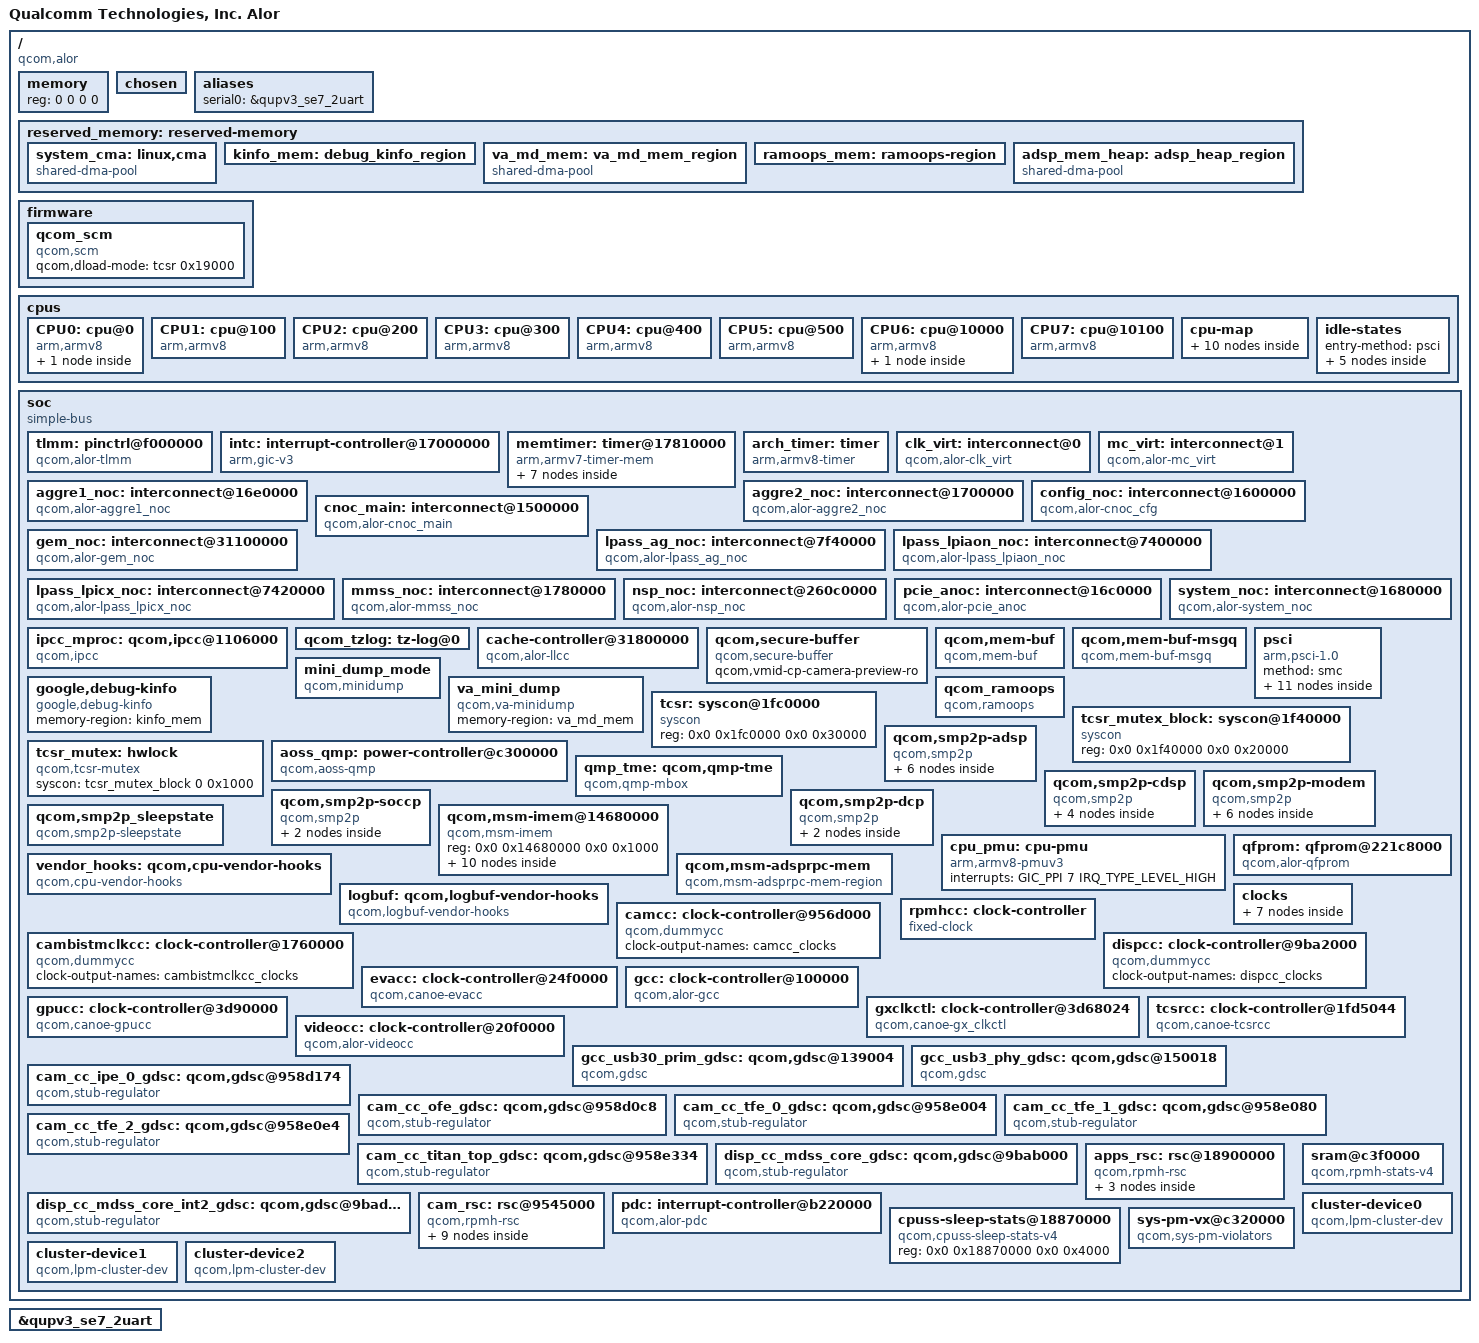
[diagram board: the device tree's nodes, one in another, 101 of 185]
// SPDX-License-Identifier: BSD-3-Clause
/*
 * Copyright (c) 2024-2025 Qualcomm Innovation Center, Inc. All rights reserved.
 */

#include <dt-bindings/clock/qcom,alor-cambistmclkcc.h>
#include <dt-bindings/clock/qcom,alor-camcc.h>
#include <dt-bindings/clock/qcom,alor-dispcc.h>
#include <dt-bindings/clock/qcom,evacc-canoe.h>
#include <dt-bindings/clock/qcom,alor-gcc.h>
#include <dt-bindings/clock/qcom,gpucc-canoe.h>
#include <dt-bindings/clock/qcom,gxclkctl-canoe.h>
#include <dt-bindings/clock/qcom,tcsrcc-canoe.h>
#include <dt-bindings/clock/qcom,videocc-canoe.h>
#include <dt-bindings/clock/qcom,rpmh.h>
#include <dt-bindings/interrupt-controller/arm-gic.h>
#include <dt-bindings/soc/qcom,rpmh-rsc.h>
#include <dt-bindings/interconnect/qcom,icc.h>
#include <dt-bindings/interconnect/qcom,alor.h>
#include <dt-bindings/soc/qcom,ipcc.h>
#include <dt-bindings/mailbox/qcom-ipcc-canoe.h>

/ {
	model = "Qualcomm Technologies, Inc. Alor";
	compatible = "qcom,alor";
	qcom,msm-id = <685 0x10000>;
	interrupt-parent = <&intc>;

	#address-cells = <2>;
	#size-cells = <2>;
	memory { device_type = "memory"; reg = <0 0 0 0>; };


	chosen: chosen {
		bootargs = "loglevel=6 kpti=0 loop.max_part=7 log_buf_len=512K kernel.panic_on_rcu_stall=1 msm_rtb.filter=0x237 rcupdate.rcu_expedited=1 rcu_nocbs=0-7 ftrace_dump_on_oops cpufreq.default_governor=performance printk.console_no_auto_verbose=1 irqaffinity=0-1";
		stdout-path = "/soc/qcom,qupv3_1_geni_se@ac0000/qcom,qup_uart@a9c000:115200n8";
	};

	aliases {
		serial0 = &qupv3_se7_2uart;
	};

	reserved_memory: reserved-memory { };

	firmware: firmware {
		qcom_scm: qcom_scm {
			compatible = "qcom,scm";
			qcom,dload-mode = <&tcsr 0x19000>;
		};
	};

	cpus {
		#address-cells = <2>;
		#size-cells = <0>;

		CPU0: cpu@0 {
			device_type = "cpu";
			compatible = "arm,armv8";
			reg = <0x0 0x0>;
			enable-method = "psci";
			cpu-idle-states = <&MEDIUM_OFF_C4>;
			power-domains = <&CPU_PD0>;
			power-domain-names = "psci";
			capacity-dmips-mhz = <1024>;
			dynamic-power-coefficient = <100>;
			next-level-cache = <&L2_0>;
			L2_0: l2-cache {
				compatible = "cache";
				cache-level = <2>;
			};
		};

		CPU1: cpu@100 {
			device_type = "cpu";
			compatible = "arm,armv8";
			reg = <0x0 0x100>;
			enable-method = "psci";
			cpu-idle-states = <&MEDIUM_OFF_C4>;
			power-domains = <&CPU_PD1>;
			power-domain-names = "psci";
			capacity-dmips-mhz = <1024>;
			dynamic-power-coefficient = <100>;
			next-level-cache = <&L2_0>;
		};

		CPU2: cpu@200 {
			device_type = "cpu";
			compatible = "arm,armv8";
			reg = <0x0 0x200>;
			enable-method = "psci";
			cpu-idle-states = <&MEDIUM_OFF_C4>;
			power-domains = <&CPU_PD2>;
			power-domain-names = "psci";
			capacity-dmips-mhz = <1024>;
			dynamic-power-coefficient = <100>;
			next-level-cache = <&L2_0>;
		};

		CPU3: cpu@300 {
			device_type = "cpu";
			compatible = "arm,armv8";
			reg = <0x0 0x300>;
			enable-method = "psci";
			cpu-idle-states = <&MEDIUM_OFF_C4>;
			power-domains = <&CPU_PD3>;
			power-domain-names = "psci";
			capacity-dmips-mhz = <1024>;
			dynamic-power-coefficient = <100>;
			next-level-cache = <&L2_0>;
		};

		CPU4: cpu@400 {
			device_type = "cpu";
			compatible = "arm,armv8";
			reg = <0x0 0x400>;
			enable-method = "psci";
			cpu-idle-states = <&MEDIUM_OFF_C4>;
			power-domains = <&CPU_PD4>;
			power-domain-names = "psci";
			capacity-dmips-mhz = <1024>;
			dynamic-power-coefficient = <100>;
			next-level-cache = <&L2_0>;
		};

		CPU5: cpu@500 {
			device_type = "cpu";
			compatible = "arm,armv8";
			reg = <0x0 0x500>;
			enable-method = "psci";
			cpu-idle-states = <&MEDIUM_OFF_C4>;
			power-domains = <&CPU_PD5>;
			power-domain-names = "psci";
			capacity-dmips-mhz = <1024>;
			dynamic-power-coefficient = <100>;
			next-level-cache = <&L2_0>;
		};

		CPU6: cpu@10000 {
			device_type = "cpu";
			compatible = "arm,armv8";
			reg = <0x0 0x10000>;
			enable-method = "psci";
			cpu-idle-states = <&LARGE_OFF_C4>;
			power-domains = <&CPU_PD6>;
			power-domain-names = "psci";
			capacity-dmips-mhz = <1208>;
			dynamic-power-coefficient = <271>;
			next-level-cache = <&L2_6>;
			L2_6: l2-cache {
				compatible = "cache";
				cache-level = <2>;
			};
		};

		CPU7: cpu@10100 {
			device_type = "cpu";
			compatible = "arm,armv8";
			reg = <0x0 0x10100>;
			enable-method = "psci";
			cpu-idle-states = <&LARGE_OFF_C4>;
			power-domains = <&CPU_PD7>;
			power-domain-names = "psci";
			capacity-dmips-mhz = <1208>;
			dynamic-power-coefficient = <271>;
			next-level-cache = <&L2_6>;
		};

		cpu-map {
			cluster0 {
				core0 {
					cpu = <&CPU0>;
				};

				core1 {
					cpu = <&CPU1>;
				};

				core2 {
					cpu = <&CPU2>;
				};

				core3 {
					cpu = <&CPU3>;
				};

				core4 {
					cpu = <&CPU4>;
				};

				core5 {
					cpu = <&CPU5>;
				};
			};

			cluster1 {
				core0 {
					cpu = <&CPU6>;
				};

				core1 {
					cpu = <&CPU7>;
				};
			};
		};

		idle-states {
			entry-method = "psci";

			MEDIUM_OFF_C4: medium-cluster0-c4 { /* C4 */
				compatible = "arm,idle-state";
				idle-state-name = "ret";
				entry-latency-us = <93>;
				exit-latency-us = <129>;
				min-residency-us = <560>;
				arm,psci-suspend-param = <0x00000004>;
			};

			LARGE_OFF_C4: large-cluster1-c4 { /* C4 */
				compatible = "arm,idle-state";
				idle-state-name = "ret";
				entry-latency-us = <172>;
				exit-latency-us = <130>;
				min-residency-us = <686>;
				arm,psci-suspend-param = <0x00000004>;
			};

			MEDIUM_CLUSTER_PWR_DN: medium-cluster-cl5 { /* CL5 */
				compatible = "domain-idle-state";
				entry-latency-us = <2150>;
				exit-latency-us = <1983>;
				min-residency-us = <9144>;
				arm,psci-suspend-param = <0x01000054>;
			};

			LARGE_CLUSTER_PWR_DN: large-cluster-cl5 { /* CL5 */
				compatible = "domain-idle-state";
				entry-latency-us = <2150>;
				exit-latency-us = <1983>;
				min-residency-us = <9144>;
				arm,psci-suspend-param = <0x01000054>;
			};

			APSS_OFF: cluster-ss3 { /* SS3 */
				compatible = "domain-idle-state";
				entry-latency-us = <2800>;
				exit-latency-us = <4400>;
				min-residency-us = <10150>;
				arm,psci-suspend-param = <0x0200B354>;
			};
		};
	};

	soc: soc { };
};

#include "alor-reserved-memory.dtsi"
#include "msm-arm-smmu-alor.dtsi"
#include "alor-dma-heaps.dtsi"

&reserved_memory {
	#address-cells = <2>;
	#size-cells = <2>;
	ranges;

	/* global autoconfigured region for contiguous allocations */
	system_cma: linux,cma {
		compatible = "shared-dma-pool";
		alloc-ranges = <0x0 0x00000000 0x0 0xffffffff>;
		reusable;
		alignment = <0x0 0x400000>;
		size = <0x0 0x2400000>;
		linux,cma-default;
	};

	kinfo_mem: debug_kinfo_region {
		alloc-ranges = <0x0 0x00000000 0xffffffff 0xffffffff>;
		size = <0x0 0x1000>;
		no-map;
	};

	va_md_mem: va_md_mem_region {
		compatible = "shared-dma-pool";
		alloc-ranges = <0x0 0x00000000 0x0 0xffffffff>;
		reusable;
		size = <0 0x1000000>;
	};

	ramoops_mem: ramoops-region {
		alloc-ranges = <0x1 0x00000000 0xfffffffe 0xffffffff>;
		size = <0x0 0x200000>;
		no-map;
	};

	adsp_mem_heap: adsp_heap_region {
		compatible = "shared-dma-pool";
		alloc-ranges = <0x0 0x00000000 0x0 0xffffffff>;
		reusable;
		alignment = <0x0 0x400000>;
		size = <0x0 0xC00000>;
	};
};

&soc {
	#address-cells = <2>;
	#size-cells = <2>;
	ranges = <0 0 0 0 0x10 0>;
	compatible = "simple-bus";

	tlmm: pinctrl@f000000 {
		compatible = "qcom,alor-tlmm";
		reg = <0x0 0xf000000 0x0 0x1000000>;
		interrupts = <GIC_SPI 208 IRQ_TYPE_LEVEL_HIGH>;
		gpio-controller;
		#gpio-cells = <2>;
		interrupt-controller;
		#interrupt-cells = <2>;
		wakeup-parent = <&pdc>;
	};

	intc: interrupt-controller@17000000 {
		compatible = "arm,gic-v3";
		#interrupt-cells = <3>;
		interrupt-controller;
		#redistributor-regions = <1>;
		redistributor-stride = <0x0 0x40000>;
		reg = <0x0 0x17000000 0x0 0x10000>,	/* GICD */
		      <0x0 0x17080000 0x0 0x200000>;	/* GICR * 8 */
		interrupts = <GIC_PPI 9 IRQ_TYPE_LEVEL_HIGH>;
	};

	memtimer: timer@17810000 {
		#address-cells = <1>;
		#size-cells = <1>;
		ranges;
		compatible = "arm,armv7-timer-mem";
		reg = <0x0 0x17810000 0x0 0x1000>;
		clock-frequency = <19200000>;

		frame@17811000 {
			frame-number = <0>;
			interrupts = <GIC_SPI 8 IRQ_TYPE_LEVEL_HIGH>,
				     <GIC_SPI 6 IRQ_TYPE_LEVEL_HIGH>;
			reg = <0x17811000 0x1000>,
			      <0x17812000 0x1000>;
		};

		frame@17813000 {
			frame-number = <1>;
			interrupts = <GIC_SPI 9 IRQ_TYPE_LEVEL_HIGH>;
			reg = <0x17813000 0x1000>;
			status = "disabled";
		};

		frame@17815000 {
			frame-number = <2>;
			interrupts = <GIC_SPI 10 IRQ_TYPE_LEVEL_HIGH>;
			reg = <0x17815000 0x1000>;
			status = "disabled";
		};

		frame@17817000 {
			frame-number = <3>;
			interrupts = <GIC_SPI 11 IRQ_TYPE_LEVEL_HIGH>;
			reg = <0x17817000 0x1000>;
			status = "disabled";
		};

		frame@17819000 {
			frame-number = <4>;
			interrupts = <GIC_SPI 12 IRQ_TYPE_LEVEL_HIGH>;
			reg = <0x17819000 0x1000>;
			status = "disabled";
		};

		frame@1781b000 {
			frame-number = <5>;
			interrupts = <GIC_SPI 13 IRQ_TYPE_LEVEL_HIGH>;
			reg = <0x1781b000 0x1000>;
			status = "disabled";
		};

		frame@1781d000 {
			frame-number = <6>;
			interrupts = <GIC_SPI 14 IRQ_TYPE_LEVEL_HIGH>;
			reg = <0x1781d000 0x1000>;
			status = "disabled";
		};
	};

	arch_timer: timer {
		compatible = "arm,armv8-timer";
		interrupts = <GIC_PPI 13 (GIC_CPU_MASK_SIMPLE(8) | IRQ_TYPE_LEVEL_LOW)>,
			     <GIC_PPI 14 (GIC_CPU_MASK_SIMPLE(8) | IRQ_TYPE_LEVEL_LOW)>,
			     <GIC_PPI 11 (GIC_CPU_MASK_SIMPLE(8) | IRQ_TYPE_LEVEL_LOW)>,
			     <GIC_PPI 10 (GIC_CPU_MASK_SIMPLE(8) | IRQ_TYPE_LEVEL_LOW)>;
		clock-frequency = <19200000>;
	};

	clk_virt: interconnect@0 {
		compatible = "qcom,alor-clk_virt";
		#interconnect-cells = <1>;
		qcom,bcm-voter-names = "hlos";
		qcom,bcm-voters = <&apps_bcm_voter>;
		qcom,skip-qos;
	};

	mc_virt: interconnect@1 {
		compatible = "qcom,alor-mc_virt";
		#interconnect-cells = <1>;
		qcom,bcm-voter-names = "hlos";
		qcom,bcm-voters = <&apps_bcm_voter>;
		qcom,skip-qos;
	};

	aggre1_noc: interconnect@16e0000 {
		compatible = "qcom,alor-aggre1_noc";
		reg = <0x0 0x16e0000 0x0 0x16400>;
		#interconnect-cells = <1>;
		qcom,bcm-voter-names = "hlos";
		qcom,bcm-voters = <&apps_bcm_voter>;
		qcom,skip-qos;
	};

	aggre2_noc: interconnect@1700000 {
		compatible = "qcom,alor-aggre2_noc";
		reg = <0x0 0x1700000 0x0 0x22400>;
		#interconnect-cells = <1>;
		qcom,bcm-voter-names = "hlos";
		qcom,bcm-voters = <&apps_bcm_voter>;
		qcom,skip-qos;
	};

	config_noc: interconnect@1600000 {
		compatible = "qcom,alor-cnoc_cfg";
		reg = <0x0 0x1600000 0x0 0x9200>;
		#interconnect-cells = <1>;
		qcom,bcm-voter-names = "hlos";
		qcom,bcm-voters = <&apps_bcm_voter>;
		qcom,skip-qos;
	};

	cnoc_main: interconnect@1500000 {
		compatible = "qcom,alor-cnoc_main";
		reg = <0x0 0x1500000 0x0 0x1a080>;
		#interconnect-cells = <1>;
		qcom,bcm-voter-names = "hlos";
		qcom,bcm-voters = <&apps_bcm_voter>;
		qcom,skip-qos;
	};

	gem_noc: interconnect@31100000 {
		compatible = "qcom,alor-gem_noc";
		reg = <0x0 0x31100000 0x0 0x153080>;
		#interconnect-cells = <1>;
		qcom,bcm-voter-names = "hlos";
		qcom,bcm-voters = <&apps_bcm_voter>;
		qcom,skip-qos;
	};

	lpass_ag_noc: interconnect@7f40000 {
		compatible = "qcom,alor-lpass_ag_noc";
		reg = <0x0 0x7f40000 0x0 0xe080>;
		#interconnect-cells = <1>;
		qcom,bcm-voter-names = "hlos";
		qcom,bcm-voters = <&apps_bcm_voter>;
		qcom,skip-qos;
	};

	lpass_lpiaon_noc: interconnect@7400000 {
		compatible = "qcom,alor-lpass_lpiaon_noc";
		reg = <0x0 0x7400000 0x0 0x19080>;
		#interconnect-cells = <1>;
		qcom,bcm-voter-names = "hlos";
		qcom,bcm-voters = <&apps_bcm_voter>;
		qcom,skip-qos;
	};

	lpass_lpicx_noc: interconnect@7420000 {
		compatible = "qcom,alor-lpass_lpicx_noc";
		reg = <0x0 0x7420000 0x0 0x44080>;
		#interconnect-cells = <1>;
		qcom,bcm-voter-names = "hlos";
		qcom,bcm-voters = <&apps_bcm_voter>;
		qcom,skip-qos;
	};

	mmss_noc: interconnect@1780000 {
		compatible = "qcom,alor-mmss_noc";
		reg = <0x0 0x1780000 0x0 0x7d400>;
		#interconnect-cells = <1>;
		qcom,bcm-voter-names = "hlos";
		qcom,bcm-voters = <&apps_bcm_voter>;
		qcom,skip-qos;
	};

	nsp_noc: interconnect@260c0000 {
		compatible = "qcom,alor-nsp_noc";
		reg = <0x0 0x260c0000 0x0 0x1c080>;
		#interconnect-cells = <1>;
		qcom,bcm-voter-names = "hlos";
		qcom,bcm-voters = <&apps_bcm_voter>;
		qcom,skip-qos;
	};

	pcie_anoc: interconnect@16c0000 {
		compatible = "qcom,alor-pcie_anoc";
		reg = <0x0 0x16c0000 0x0 0x11400>;
		#interconnect-cells = <1>;
		qcom,bcm-voter-names = "hlos";
		qcom,bcm-voters = <&apps_bcm_voter>;
		qcom,skip-qos;
	};

	system_noc: interconnect@1680000 {
		compatible = "qcom,alor-system_noc";
		reg = <0x0 0x1680000 0x0 0x1f080>;
		#interconnect-cells = <1>;
		qcom,bcm-voter-names = "hlos";
		qcom,bcm-voters = <&apps_bcm_voter>;
		qcom,skip-qos;
	};

	ipcc_mproc: qcom,ipcc@1106000 {
		compatible = "qcom,ipcc";
		reg = <0x0 0x1106000 0x0 0x1000>;
		interrupts = <GIC_SPI 246 IRQ_TYPE_LEVEL_HIGH>;
		interrupt-controller;
		#interrupt-cells = <3>;
		#mbox-cells = <2>;
	};

	qcom_tzlog: tz-log@0 {
	};

	cache-controller@31800000 {
		compatible = "qcom,alor-llcc";
		reg = <0x0 0x31800000 0x0 0x200000>, <0x0 0x32800000 0x0 0x200000>,
			<0x0 0x31C00000 0x0 0x200000>, <0x0 0x32C00000 0x0 0x200000>,
			<0x0 0x34800000 0x0 0x200000>, <0x0 0x34C00000 0x0 0x200000>;
		reg-names = "llcc0_base", "llcc1_base", "llcc2_base",
			"llcc3_base", "llcc_broadcast_or_base",
			"llcc_broadcast_and_base";
		interrupts = <GIC_SPI 266 IRQ_TYPE_LEVEL_HIGH>;
		cap-based-alloc-and-pwr-collapse;
	};

	qcom,secure-buffer {
		compatible = "qcom,secure-buffer";
		qcom,vmid-cp-camera-preview-ro;
	};

	qcom,mem-buf {
		compatible = "qcom,mem-buf";
		qcom,mem-buf-capabilities = "supplier";
		qcom,vmid = <3>;
	};

	qcom,mem-buf-msgq {
		compatible = "qcom,mem-buf-msgq";
	};

	psci {
		compatible = "arm,psci-1.0";
		method = "smc";

		CPU_PD0: cpu-pd0 {
			#power-domain-cells = <0>;
			power-domains = <&CLUSTER_PD0>;
		};

		CPU_PD1: cpu-pd1 {
			#power-domain-cells = <0>;
			power-domains = <&CLUSTER_PD0>;
		};

		CPU_PD2: cpu-pd2 {
			#power-domain-cells = <0>;
			power-domains = <&CLUSTER_PD0>;
		};

		CPU_PD3: cpu-pd3 {
			#power-domain-cells = <0>;
			power-domains = <&CLUSTER_PD0>;
		};

		CPU_PD4: cpu-pd4 {
			#power-domain-cells = <0>;
			power-domains = <&CLUSTER_PD0>;
		};

		CPU_PD5: cpu-pd5 {
			#power-domain-cells = <0>;
			power-domains = <&CLUSTER_PD0>;
		};

		CPU_PD6: cpu-pd6 {
			#power-domain-cells = <0>;
			power-domains = <&CLUSTER_PD1>;
		};

		CPU_PD7: cpu-pd7 {
			#power-domain-cells = <0>;
			power-domains = <&CLUSTER_PD1>;
		};

		CLUSTER_PD0: cluster-pd0 {
			#power-domain-cells = <0>;
			power-domains = <&CLUSTER_PD2>;
			domain-idle-states = <&MEDIUM_CLUSTER_PWR_DN>;
		};

		CLUSTER_PD1: cluster-pd1 {
			#power-domain-cells = <0>;
			power-domains = <&CLUSTER_PD2>;
			domain-idle-states = <&LARGE_CLUSTER_PWR_DN>;
		};

		CLUSTER_PD2: cluster-pd2 {
			#power-domain-cells = <0>;
			domain-idle-states = <&APSS_OFF>;
		};
	};

	google,debug-kinfo {
		compatible = "google,debug-kinfo";
		memory-region = <&kinfo_mem>;
	};

	mini_dump_mode {
		compatible = "qcom,minidump";
		status = "ok";
	};

	va_mini_dump {
		compatible = "qcom,va-minidump";
		memory-region = <&va_md_mem>;
		status = "ok";
	};

	qcom_ramoops {
		compatible = "qcom,ramoops";
		memory-region = <&ramoops_mem>;
		pmsg-size = <0x200000>;
		mem-type = <2>;
	};

	tcsr: syscon@1fc0000 {
		compatible = "syscon";
		reg = <0x0 0x1fc0000 0x0 0x30000>;
	};

	tcsr_mutex_block: syscon@1f40000 {
		compatible = "syscon";
		reg = <0x0 0x1f40000 0x0 0x20000>;
	};

	tcsr_mutex: hwlock {
		compatible = "qcom,tcsr-mutex";
		syscon = <&tcsr_mutex_block 0 0x1000>;
		#hwlock-cells = <1>;
	};

	aoss_qmp: power-controller@c300000 {
		compatible = "qcom,aoss-qmp";
		reg = <0x0 0xc300000 0x0 0x400>;
		interrupt-parent = <&ipcc_mproc>;
		interrupts = <IPCC_MPROC_AOP
			      IPCC_MPROC_SIGNAL_GLINK_QMP
			      IRQ_TYPE_EDGE_RISING>;
		mboxes = <&ipcc_mproc IPCC_MPROC_AOP
			  IPCC_MPROC_SIGNAL_GLINK_QMP>;

		#power-domain-cells = <1>;
		#clock-cells = <0>;
	};

	qmp_tme: qcom,qmp-tme {
		compatible = "qcom,qmp-mbox";
		qcom,remote-pid = <14>;
		mboxes = <&ipcc_mproc IPCC_MPROC_TME
			  IPCC_MPROC_SIGNAL_GLINK_QMP>;
		mbox-names = "tme_qmp";
		interrupt-parent = <&ipcc_mproc>;
		interrupts = <IPCC_MPROC_TME
			      IPCC_MPROC_SIGNAL_GLINK_QMP
			      IRQ_TYPE_EDGE_RISING>;

		label = "tme";
		qcom,early-boot;
		priority = <0>;
		mbox-desc-offset = <0x0>;
		#mbox-cells = <1>;
	};

	qcom,smp2p-adsp {
		compatible = "qcom,smp2p";
		qcom,smem = <443>, <429>;
		interrupt-parent = <&ipcc_mproc>;
		interrupts = <IPCC_MPROC_LPASS IPCC_MPROC_SIGNAL_SMP2P
			      IRQ_TYPE_EDGE_RISING>;
		mboxes = <&ipcc_mproc IPCC_MPROC_LPASS
			  IPCC_MPROC_SIGNAL_SMP2P>;
		qcom,local-pid = <0>;
		qcom,remote-pid = <2>;

		adsp_smp2p_out: master-kernel {
			qcom,entry-name = "master-kernel";
			#qcom,smem-state-cells = <1>;
		};

		adsp_smp2p_in: slave-kernel {
			qcom,entry-name = "slave-kernel";
			interrupt-controller;
			#interrupt-cells = <2>;
		};

		sleepstate_smp2p_out: sleepstate-out {
			qcom,entry-name = "sleepstate";
			#qcom,smem-state-cells = <1>;
		};

		sleepstate_smp2p_in: qcom,sleepstate-in {
			qcom,entry-name = "sleepstate_see";
			interrupt-controller;
			#interrupt-cells = <2>;
		};

		smp2p_rdbg2_out: qcom,smp2p-rdbg2-out {
			qcom,entry-name = "rdbg";
			#qcom,smem-state-cells = <1>;
		};

		smp2p_rdbg2_in: qcom,smp2p-rdbg2-in {
			qcom,entry-name = "rdbg";
			interrupt-controller;
			#interrupt-cells = <2>;
		};
	};

	qcom,smp2p-cdsp {
		compatible = "qcom,smp2p";
		qcom,smem = <94>, <432>;
		interrupt-parent = <&ipcc_mproc>;
		interrupts = <IPCC_MPROC_CDSP IPCC_MPROC_SIGNAL_SMP2P
			      IRQ_TYPE_EDGE_RISING>;
		mboxes = <&ipcc_mproc IPCC_MPROC_CDSP IPCC_MPROC_SIGNAL_SMP2P>;
		qcom,local-pid = <0>;
		qcom,remote-pid = <5>;

		cdsp_smp2p_out: master-kernel {
			qcom,entry-name = "master-kernel";
			#qcom,smem-state-cells = <1>;
		};

		cdsp_smp2p_in: slave-kernel {
			qcom,entry-name = "slave-kernel";
			interrupt-controller;
			#interrupt-cells = <2>;
		};

		smp2p_rdbg5_out: qcom,smp2p-rdbg5-out {
			qcom,entry-name = "rdbg";
			#qcom,smem-state-cells = <1>;
		};

		smp2p_rdbg5_in: qcom,smp2p-rdbg5-in {
			qcom,entry-name = "rdbg";
			interrupt-controller;
			#interrupt-cells = <2>;
		};
	};

	qcom,smp2p-modem {
		compatible = "qcom,smp2p";
		qcom,smem = <435>, <428>;
		interrupt-parent = <&ipcc_mproc>;
		interrupts = <IPCC_MPROC_MPSS IPCC_MPROC_SIGNAL_SMP2P
			      IRQ_TYPE_EDGE_RISING>;
		mboxes = <&ipcc_mproc IPCC_MPROC_MPSS IPCC_MPROC_SIGNAL_SMP2P>;
		qcom,local-pid = <0>;
		qcom,remote-pid = <1>;

		modem_smp2p_out: master-kernel {
			qcom,entry-name = "master-kernel";
			#qcom,smem-state-cells = <1>;
		};

		modem_smp2p_in: slave-kernel {
			qcom,entry-name = "slave-kernel";
			interrupt-controller;
			#interrupt-cells = <2>;
		};

		smp2p_ipa_1_out: qcom,smp2p-ipa-1-out {
			qcom,entry-name = "ipa";
			#qcom,smem-state-cells = <1>;
		};

		/* ipa - inbound entry from mss */
		smp2p_ipa_1_in: qcom,smp2p-ipa-1-in {
			qcom,entry-name = "ipa";
			interrupt-controller;
			#interrupt-cells = <2>;
		};

		smp2p_smem_mailbox_1_out: qcom,smp2p-smem-mailbox-1-out {
			qcom,entry-name = "smem-mailbox";
			#qcom,smem-state-cells = <1>;
		};

		smp2p_smem_mailbox_1_in: qcom,smp2p-smem-mailbox-1-in {
			qcom,entry-name = "smem-mailbox";
			interrupt-controller;
			#interrupt-cells = <2>;
		};
	};

	qcom,smp2p-soccp {
		compatible = "qcom,smp2p";
		qcom,smem = <617>, <616>;
		interrupt-parent = <&ipcc_mproc>;
		interrupts = <IPCC_MPROC_SOCCP IPCC_MPROC_SIGNAL_SMP2P
			      IRQ_TYPE_EDGE_RISING>;
		mboxes = <&ipcc_mproc IPCC_MPROC_SOCCP IPCC_MPROC_SIGNAL_SMP2P>;
		qcom,local-pid = <0>;
		qcom,remote-pid = <19>;

		soccp_smp2p_out: master-kernel {
			qcom,entry-name = "master-kernel";
			#qcom,smem-state-cells = <1>;
		};

		soccp_smp2p_in: slave-kernel {
			qcom,entry-name = "slave-kernel";
			interrupt-controller;
			#interrupt-cells = <2>;
		};
	};

	qcom,smp2p-dcp {
		compatible = "qcom,smp2p";
		qcom,smem = <617>, <616>;
		interrupt-parent = <&ipcc_mproc>;
		interrupts = <IPCC_MPROC_DCP IPCC_MPROC_SIGNAL_SMP2P
			      IRQ_TYPE_EDGE_RISING>;
		mboxes = <&ipcc_mproc IPCC_MPROC_DCP IPCC_MPROC_SIGNAL_SMP2P>;
		qcom,local-pid = <0>;
		qcom,remote-pid = <22>;

		dcp_smp2p_out: master-kernel {
			qcom,entry-name = "master-kernel";
			#qcom,smem-state-cells = <1>;
		};

		dcp_smp2p_in: slave-kernel {
			qcom,entry-name = "slave-kernel";
			interrupt-controller;
			#interrupt-cells = <2>;
		};
	};

	qcom,smp2p_sleepstate {
		compatible = "qcom,smp2p-sleepstate";
		qcom,smem-states = <&sleepstate_smp2p_out 0>;
		interrupt-parent = <&sleepstate_smp2p_in>;
		interrupts = <0 0>;
		interrupt-names = "smp2p-sleepstate-in";
	};

	qcom,msm-imem@14680000 {
		compatible = "qcom,msm-imem";
		reg = <0x0 0x14680000 0x0 0x1000>;
		ranges = <0x0 0x0 0x14680000 0x1000>;
		#address-cells = <1>;
		#size-cells = <1>;

		mem_dump_table@10 {
			compatible = "qcom,msm-imem-mem_dump_table";
			reg = <0x10 0x8>;
		};

		restart_reason@65c {
			compatible = "qcom,msm-imem-restart_reason";
			reg = <0x65c 0x4>;
		};

		dload_type@1c {
			compatible = "qcom,msm-imem-dload-type";
			reg = <0x1c 0x4>;
		};

		boot_stats@6b0 {
			compatible = "qcom,msm-imem-boot_stats";
			reg = <0x6b0 0x20>;
		};

		kaslr_offset@6d0 {
			compatible = "qcom,msm-imem-kaslr_offset";
			reg = <0x6d0 0xc>;
		};

		pil@94c {
			compatible = "qcom,pil-reloc-info";
			reg = <0x94c 0xc8>;
		};

		pil@6dc {
			compatible = "qcom,msm-imem-pil-disable-timeout";
			reg = <0x6dc 0x4>;
		};

		diag_dload@c8 {
			compatible = "qcom,msm-imem-diag-dload";
			reg = <0xc8 0xc8>;
		};

		modem_dsm@c98 {
			compatible = "qcom,msm-imem-mss-dsm";
			reg = <0xc98 0x10>;
		};

		sys_dbg@af8 {
			compatible = "qcom,msm-imem-gpu-dump-skip";
			reg = <0xb0c 0x4>;
		};
	};

	cpu_pmu: cpu-pmu {
		compatible = "arm,armv8-pmuv3";
		interrupts = <GIC_PPI 7 IRQ_TYPE_LEVEL_HIGH>;
	};

	vendor_hooks: qcom,cpu-vendor-hooks {
		compatible = "qcom,cpu-vendor-hooks";
	};

	logbuf: qcom,logbuf-vendor-hooks {
		compatible = "qcom,logbuf-vendor-hooks";
	};

	qfprom: qfprom@221c8000 {
		compatible = "qcom,alor-qfprom", "qcom,qfprom";
		reg = <0x0 0x221c8000 0x0 0x1000>;
		#address-cells = <1>;
		#size-cells = <1>;
		read-only;
		ranges;
	};

	qcom,msm-adsprpc-mem {
		compatible = "qcom,msm-adsprpc-mem-region";
		memory-region = <&adsp_mem_heap>;
		restrict-access;
	};

	clocks {
		xo_board: xo_board {
			compatible = "fixed-clock";
			clock-frequency = <76800000>;
			clock-output-names = "xo_board";
			#clock-cells = <0>;
		};

		sleep_clk: sleep_clk {
			compatible = "fixed-clock";
			clock-frequency = <32000>;
			clock-output-names = "sleep_clk";
			#clock-cells = <0>;
		};

		pcie_0_pipe_clk: pcie_0_pipe_clk {
			compatible = "fixed-clock";
			clock-frequency = <1000>;
			clock-output-names = "pcie_0_pipe_clk";
			#clock-cells = <0>;
		};

		ufs_phy_rx_symbol_0_clk: ufs_phy_rx_symbol_0_clk {
			compatible = "fixed-clock";
			clock-frequency = <1000>;
			clock-output-names = "ufs_phy_rx_symbol_0_clk";
			#clock-cells = <0>;
		};

		ufs_phy_rx_symbol_1_clk: ufs_phy_rx_symbol_1_clk {
			compatible = "fixed-clock";
			clock-frequency = <1000>;
			clock-output-names = "ufs_phy_rx_symbol_1_clk";
			#clock-cells = <0>;
		};

		ufs_phy_tx_symbol_0_clk: ufs_phy_tx_symbol_0_clk {
			compatible = "fixed-clock";
			clock-frequency = <1000>;
			clock-output-names = "ufs_phy_tx_symbol_0_clk";
			#clock-cells = <0>;
		};

		usb3_phy_wrapper_gcc_usb30_pipe_clk: usb3_phy_wrapper_gcc_usb30_pipe_clk {
			compatible = "fixed-clock";
			clock-frequency = <1000>;
			clock-output-names = "usb3_phy_wrapper_gcc_usb30_pipe_clk";
			#clock-cells = <0>;
		};
	};

	rpmhcc: clock-controller {
		compatible = "fixed-clock";
		clock-output-names = "rpmh_clocks";
		clock-frequency = <19200000>;
		#clock-cells = <1>;
	};

	cambistmclkcc: clock-controller@1760000 {
		compatible = "qcom,dummycc";
		clock-output-names = "cambistmclkcc_clocks";
		#clock-cells = <1>;
		#reset-cells = <1>;
	};

	camcc: clock-controller@956d000 {
		compatible = "qcom,dummycc";
		clock-output-names = "camcc_clocks";
		#clock-cells = <1>;
		#reset-cells = <1>;
	};

	dispcc: clock-controller@9ba2000 {
		compatible = "qcom,dummycc";
		clock-output-names = "dispcc_clocks";
		#clock-cells = <1>;
		#reset-cells = <1>;
	};

	evacc: clock-controller@24f0000 {
		compatible = "qcom,canoe-evacc", "syscon";
		reg = <0x0 0x24f0000 0x0 0x10000>;
		reg-name = "cc_base";
		vdd_mm-supply = <&VDD_MM_LEVEL>;
		vdd_mxc-supply = <&VDD_MXC_LEVEL>;
		vdd_mm_mxc_voter-supply = <&VDD_MM_MXC_VOTER_LEVEL>;
		clocks = <&rpmhcc RPMH_CXO_CLK>,
			 <&rpmhcc RPMH_CXO_CLK_A>,
			 <&sleep_clk>,
			 <&gcc GCC_EVA_AHB_CLK>;
		clock-names = "bi_tcxo",
			      "bi_tcxo_ao",
			      "sleep_clk",
			      "iface";
		#clock-cells = <1>;
		#reset-cells = <1>;
		#power-domain-cells = <1>;
	};

	gcc: clock-controller@100000 {
		compatible = "qcom,alor-gcc", "syscon";
		reg = <0x0 0x100000 0x0 0x1f4200>;
		reg-name = "cc_base";
		vdd_cx-supply = <&VDD_CX_LEVEL>;
		vdd_mx-supply = <&VDD_MX_LEVEL>;
		clocks = <&rpmhcc RPMH_CXO_CLK>,
			 <&pcie_0_pipe_clk>,
			 <&sleep_clk>,
			 <&ufs_phy_rx_symbol_0_clk>,
			 <&ufs_phy_rx_symbol_1_clk>,
			 <&ufs_phy_tx_symbol_0_clk>,
			 <&usb3_phy_wrapper_gcc_usb30_pipe_clk>;
		clock-names = "bi_tcxo",
			      "pcie_0_pipe_clk",
			      "sleep_clk",
			      "ufs_phy_rx_symbol_0_clk",
			      "ufs_phy_rx_symbol_1_clk",
			      "ufs_phy_tx_symbol_0_clk",
			      "usb3_phy_wrapper_gcc_usb30_pipe_clk";
		#clock-cells = <1>;
		#reset-cells = <1>;
		#power-domain-cells = <1>;
	};

	gpucc: clock-controller@3d90000 {
		compatible = "qcom,canoe-gpucc", "syscon";
		reg = <0x0 0x3d90000 0x0 0x9800>;
		reg-name = "cc_base";
		vdd_cx-supply = <&VDD_CX_LEVEL>;
		vdd_mx-supply = <&VDD_MX_LEVEL>;
		clocks = <&rpmhcc RPMH_CXO_CLK>,
			 <&gcc GCC_GPU_GPLL0_CLK_SRC>,
			 <&gcc GCC_GPU_GPLL0_DIV_CLK_SRC>;
		clock-names = "bi_tcxo",
			      "gpll0_out_main",
			      "gpll0_out_main_div";
		#clock-cells = <1>;
		#reset-cells = <1>;
		#power-domain-cells = <1>;
	};

	gxclkctl: clock-controller@3d68024 {
		compatible = "qcom,canoe-gx_clkctl";
		reg = <0x0 0x3d68024 0x0 0x8>;
		reg-name = "cc_base";
		power-domains = <&gpucc GPU_CC_CX_GDSC>;
		vdd_gfx-supply = <&VDD_GFX_MXC_VOTER_LEVEL>;
		#power-domain-cells = <1>;
	};

	tcsrcc: clock-controller@1fd5044 {
		compatible = "qcom,canoe-tcsrcc", "syscon";
		reg = <0x0 0x1fd5044 0x0 0x1c>;
		reg-name = "cc_base";
		#clock-cells = <1>;
		#reset-cells = <1>;
	};

	videocc: clock-controller@20f0000 {
		compatible = "qcom,alor-videocc", "syscon";
		reg = <0x0 0x20f0000 0x0 0x10000>;
		reg-name = "cc_base";
		vdd_mm-supply = <&VDD_MM_LEVEL>;
		vdd_mxc-supply = <&VDD_MXC_LEVEL>;
		vdd_mm_mxc_voter-supply = <&VDD_MM_MXC_VOTER_LEVEL>;
		clocks = <&rpmhcc RPMH_CXO_CLK>,
			<&rpmhcc RPMH_CXO_CLK_A>,
			<&sleep_clk>,
			<&gcc GCC_VIDEO_AHB_CLK>;
		clock-names = "bi_tcxo",
				"bi_tcxo_ao",
				"sleep_clk",
				"iface";
		#clock-cells = <1>;
		#reset-cells = <1>;
		#power-domain-cells = <1>;
	};

	/* GCC GDSCs */
	gcc_usb30_prim_gdsc: qcom,gdsc@139004 {
		compatible = "qcom,gdsc";
		reg = <0x0 0x139004 0x0 0x4>;
		regulator-name = "gcc_usb30_prim_gdsc";
		parent-supply = <&VDD_CX_LEVEL>;
		qcom,retain-regs;
		qcom,support-cfg-gdscr;
		proxy-supply = <&gcc_usb30_prim_gdsc>;
		qcom,proxy-consumer-enable;
	};

	gcc_usb3_phy_gdsc: qcom,gdsc@150018 {
		compatible = "qcom,gdsc";
		reg = <0x0 0x150018 0x0 0x4>;
		regulator-name = "gcc_usb3_phy_gdsc";
		parent-supply = <&VDD_MX_LEVEL>;
		qcom,retain-regs;
		qcom,support-cfg-gdscr;
		proxy-supply = <&gcc_usb3_phy_gdsc>;
		qcom,proxy-consumer-enable;
	};

	/* CAM_CC GDSCs */
	cam_cc_ipe_0_gdsc: qcom,gdsc@958d174 {
		compatible = "qcom,stub-regulator";
		regulator-name = "cam_cc_ipe_0_gdsc";
		qcom,support-hw-trigger;
		qcom,support-cfg-gdscr;
	};

	cam_cc_ofe_gdsc: qcom,gdsc@958d0c8 {
		compatible = "qcom,stub-regulator";
		regulator-name = "cam_cc_ofe_gdsc";
		qcom,support-hw-trigger;
		qcom,support-cfg-gdscr;
	};

	cam_cc_tfe_0_gdsc: qcom,gdsc@958e004 {
		compatible = "qcom,stub-regulator";
		regulator-name = "cam_cc_tfe_0_gdsc";
		qcom,support-hw-trigger;
		qcom,support-cfg-gdscr;
	};

	cam_cc_tfe_1_gdsc: qcom,gdsc@958e080 {
		compatible = "qcom,stub-regulator";
		regulator-name = "cam_cc_tfe_1_gdsc";
		qcom,support-hw-trigger;
		qcom,support-cfg-gdscr;
	};

	cam_cc_tfe_2_gdsc: qcom,gdsc@958e0e4 {
		compatible = "qcom,stub-regulator";
		regulator-name = "cam_cc_tfe_2_gdsc";
		qcom,support-hw-trigger;
		qcom,support-cfg-gdscr;
	};

	cam_cc_titan_top_gdsc: qcom,gdsc@958e334 {
		compatible = "qcom,stub-regulator";
		regulator-name = "cam_cc_titan_top_gdsc";
		qcom,support-cfg-gdscr;
	};

	/* DISP_CC GDSCs */
	disp_cc_mdss_core_gdsc: qcom,gdsc@9bab000 {
		compatible = "qcom,stub-regulator";
		regulator-name = "disp_cc_mdss_core_gdsc";
		qcom,support-hw-trigger;
		qcom,support-cfg-gdscr;
	};

	disp_cc_mdss_core_int2_gdsc: qcom,gdsc@9bad000 {
		compatible = "qcom,stub-regulator";
		regulator-name = "disp_cc_mdss_core_int2_gdsc";
		qcom,support-hw-trigger;
		qcom,support-cfg-gdscr;
	};

	apps_rsc: rsc@18900000 {
		label = "apps_rsc";
		compatible = "qcom,rpmh-rsc";
		reg = <0x0 0x18900000 0x0 0x10000>,
		      <0x0 0x18910000 0x0 0x10000>,
		      <0x0 0x18920000 0x0 0x10000>;
		reg-names = "drv-0", "drv-1", "drv-2";
		qcom,drv-count = <3>;
		interrupts = <GIC_SPI 3 IRQ_TYPE_LEVEL_HIGH>,
			     <GIC_SPI 4 IRQ_TYPE_LEVEL_HIGH>,
			     <GIC_SPI 5 IRQ_TYPE_LEVEL_HIGH>;
		power-domains = <&CLUSTER_PD2>;

		apps_rsc_drv2: drv@2 {
			qcom,drv-id = <2>;
			qcom,tcs-offset = <0xd00>;
			qcom,tcs-distance = <0x2a0>;
			channel@0 {
				qcom,tcs-config = <ACTIVE_TCS    3>,
						  <SLEEP_TCS     2>,
						  <WAKE_TCS      2>,
						  <CONTROL_TCS   0>,
						  <FAST_PATH_TCS 1>;
			};

			apps_bcm_voter: bcm_voter {
				compatible = "qcom,bcm-voter";
			};
		};
	};

	cam_rsc: rsc@9545000 {
		label = "cam_rsc";
		compatible = "qcom,rpmh-rsc";
		reg = <0x0 0x9545000 0x0 0x1000>,
		      <0x0 0x9546000 0x0 0x1000>,
		      <0x0 0x9547000 0x0 0x1000>;
		reg-names = "drv-0", "drv-1", "drv-2";
		qcom,drv-count = <3>;
		qcom,hw-channel;
		interrupts = <GIC_SPI 368 IRQ_TYPE_LEVEL_HIGH>,
			     <GIC_SPI 369 IRQ_TYPE_LEVEL_HIGH>,
			     <GIC_SPI 370 IRQ_TYPE_LEVEL_HIGH>;

		cam_rsc_drv0: drv@0 {
			qcom,drv-id = <0>;
			qcom,tcs-offset = <0x520>;
			qcom,tcs-distance = <0x150>;
			channel@0 {
				qcom,tcs-config = <ACTIVE_TCS    0>,
						  <WAKE_TCS      1>,
						  <SLEEP_TCS     1>,
						  <CONTROL_TCS   0>,
						  <FAST_PATH_TCS 0>;
			};

			channel@1 {
				qcom,tcs-config = <ACTIVE_TCS    0>,
						  <WAKE_TCS      1>,
						  <SLEEP_TCS     1>,
						  <CONTROL_TCS   0>,
						  <FAST_PATH_TCS 0>;
			};
		};

		cam_rsc_drv1: drv@1 {
			qcom,drv-id = <1>;
			qcom,tcs-offset = <0x520>;
			qcom,tcs-distance = <0x150>;
			channel@0 {
				qcom,tcs-config = <ACTIVE_TCS    0>,
						  <WAKE_TCS      1>,
						  <SLEEP_TCS     1>,
						  <CONTROL_TCS   0>,
						  <FAST_PATH_TCS 0>;
			};

			channel@1 {
				qcom,tcs-config = <ACTIVE_TCS    0>,
						  <WAKE_TCS      1>,
						  <SLEEP_TCS     1>,
						  <CONTROL_TCS   0>,
						  <FAST_PATH_TCS 0>;
			};
		};

		cam_rsc_drv2: drv@2 {
			qcom,drv-id = <2>;
			qcom,tcs-offset = <0x520>;
			qcom,tcs-distance = <0x150>;
			channel@0 {
				qcom,tcs-config = <ACTIVE_TCS    0>,
						  <WAKE_TCS      1>,
						  <SLEEP_TCS     1>,
						  <CONTROL_TCS   0>,
						  <FAST_PATH_TCS 0>;
			};

			channel@1 {
				qcom,tcs-config = <ACTIVE_TCS    0>,
						  <WAKE_TCS      1>,
						  <SLEEP_TCS     1>,
						  <CONTROL_TCS   0>,
						  <FAST_PATH_TCS 0>;
			};
		};
	};

	pdc: interrupt-controller@b220000 {
		compatible = "qcom,alor-pdc", "qcom,pdc";
		reg = <0x0 0xb220000 0x0 0x10000>, <0x0 0x179600f0 0x0 0xf8>;
		qcom,pdc-ranges = <0 745 38>, <40 785 11>, <51 527 4>,
				  <58 534 2>, <61 537 20>, <84 559 14>,
				  <98 609 32>, <130 717 12>, <142 251 5>,
				  <147 796 16>, <163 783 2>, <165 531 2>,
				  <167 536 1>, <168 557 2>, <170 415 1>,
				  <171 438 1>, <172 579 1>, <173 703 1>,
				  <174 708 1>, <175 714 1>, <176 68 1>,
				  <177 86 1>, <178 96 1>, <179 249 1>,
				  <180 504 9>;
		#interrupt-cells = <2>;
		interrupt-parent = <&intc>;
		interrupt-controller;
	};

	cpuss-sleep-stats@18870000 {
		compatible = "qcom,cpuss-sleep-stats-v4";
		reg = <0x0 0x18870000 0x0 0x4000>;
		reg-names = "base";
	};

	sys-pm-vx@c320000 {
		compatible = "qcom,sys-pm-violators", "qcom,sys-pm-alor";
		reg = <0x0 0xc320000 0x0 0x400>;
		qcom,qmp = <&aoss_qmp>;
	};

	sram@c3f0000 {
		compatible = "qcom,rpmh-stats-v4";
		reg = <0x0 0xc3f0000 0x0 0x400>;
		qcom,qmp = <&aoss_qmp>;
		ss-name = "modem", "adsp", "adsp_island",
			  "cdsp", "apss", "wpss";
	};

	cluster-device0 {
		compatible = "qcom,lpm-cluster-dev";
		power-domains = <&CLUSTER_PD0>;
		qcom,pred-prem-cnt = <2>;
		qcom,sample-invalid-time = <40000000>;
	};

	cluster-device1 {
		compatible = "qcom,lpm-cluster-dev";
		power-domains = <&CLUSTER_PD1>;
		qcom,pred-prem-cnt = <2>;
		qcom,sample-invalid-time = <40000000>;
		qcom,use-cluster-bias-timer;
	};

	cluster-device2 {
		compatible = "qcom,lpm-cluster-dev";
		power-domains = <&CLUSTER_PD2>;
		qcom,pred-prem-cnt = <2>;
		qcom,sample-invalid-time = <40000000>;
	};
};

#include "alor-debug.dtsi"
#include "alor-pinctrl.dtsi"
#include "alor-stub-regulators.dtsi"
#include "alor-qupv3.dtsi"
#include "alor-usb.dtsi"

&qupv3_se7_2uart {
	status = "ok";
};
